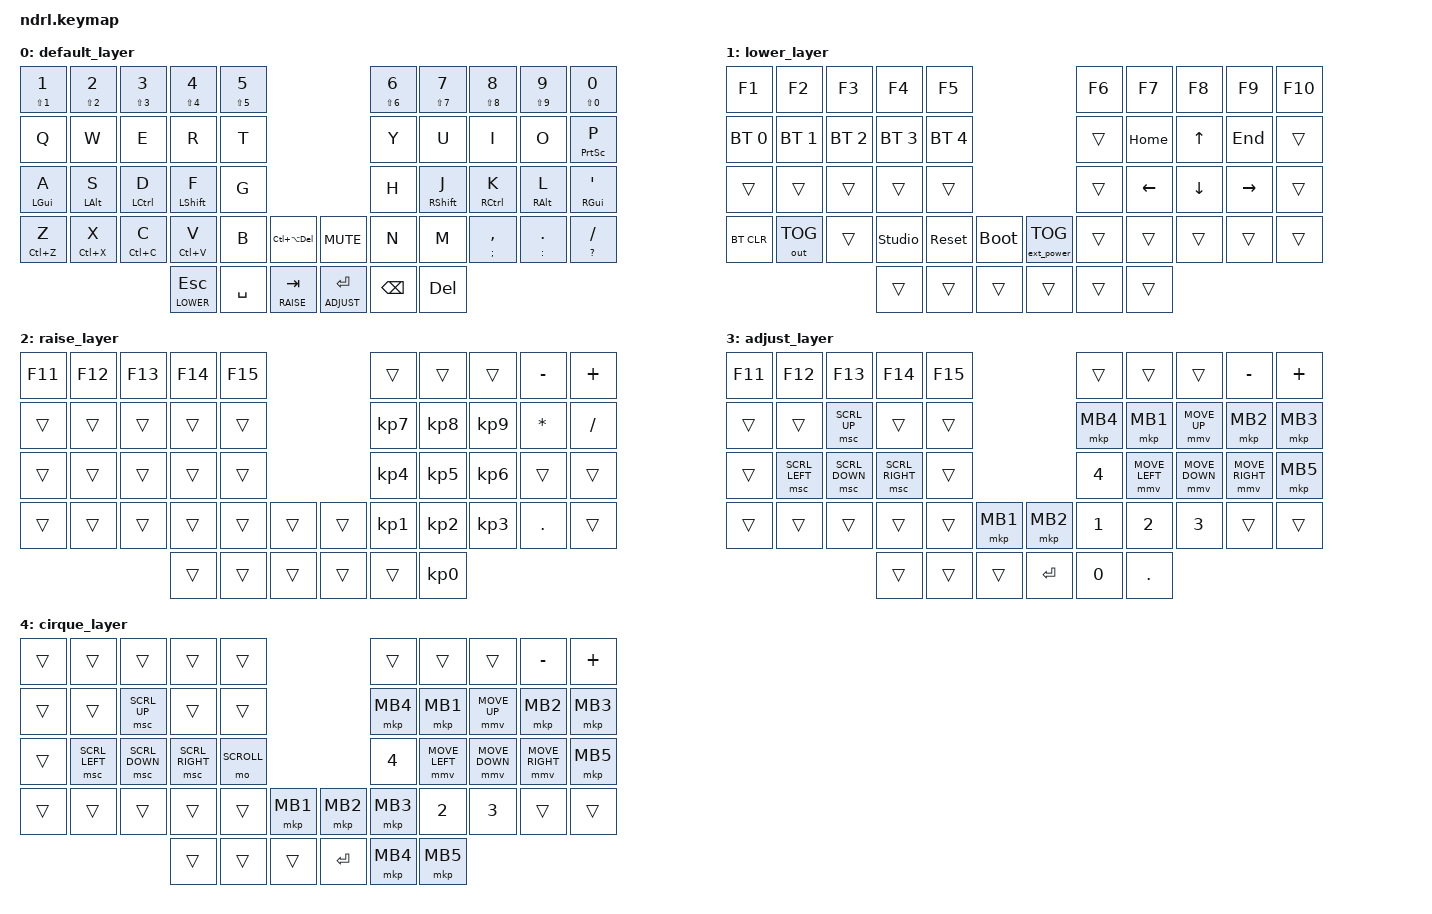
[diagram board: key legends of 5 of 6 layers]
/*
 * Copyright (c) 2024 idesignstuff
 *
 * SPDX-License-Identifier: MIT
 */

#include <behaviors.dtsi>
#include <dt-bindings/zmk/keys.h>
#include <dt-bindings/zmk/bt.h>
#include <dt-bindings/zmk/outputs.h>
#include <zephyr/dt-bindings/input/input-event-codes.h>
#include <input/processors.dtsi>
#include <dt-bindings/zmk/input_transform.h>
#include <dt-bindings/zmk/ext_power.h>
#include <dt-bindings/zmk/pointing.h>

#define DEFAULT 0
#define LOWER   1
#define RAISE   2
#define ADJUST  3
#define CIRQUE  4
#define SCROLL  5
 / {
     glidepoint_listener {
        compatible = "zmk,input-listener";
        device = <&glidepoint>;
        input-processors = 
        <&zip_xy_transform (INPUT_TRANSFORM_XY_SWAP |INPUT_TRANSFORM_X_INVERT | INPUT_TRANSFORM_Y_INVERT)>,
        <&zip_temp_layer 4 1000>;
     };
      scroller {
        layers = <1>;
        input-processors =
            <&zip_xy_to_scroll_mapper>,
            <&zip_scroll_transform (INPUT_TRANSFORM_XY_SWAP | INPUT_TRANSFORM_Y_INVERT)>,
            <&zip_scroll_scaler 1 3>;
    };
   };

/ {
    behaviors {
        // Home row mod tap settings
        hrm: home_row_mods {
            compatible = "zmk,behavior-hold-tap";
            label = "HOME_ROW_MODS";
            #binding-cells = <2>;
            tapping-term-ms = <300>;
            quick-tap-ms = <0>;
            flavor = "tap-preferred";
            bindings = <&kp>, <&kp>;
        }; // end home row mod tap settings

        pht: positional_hold_tap {
            compatible = "zmk,behavior-hold-tap";
            label = "POSITIONAL_HOLD_TAP";
            #binding-cells = <2>;
            flavor = "hold-preferred";
            tapping-term-ms = <400>;
            quick-tap-ms = <200>;
            bindings = <&kp>, <&kp>;
            hold-trigger-key-positions = <1>;    // <---[[the W key]]
            }; //end positional hold tap

       rpi: require_prior_idle {
         compatible = "zmk,behavior-hold-tap";
         #binding-cells = <2>;
         flavor = "tap-preferred";
         tapping-term-ms = <200>;
         quick-tap-ms = <200>;
         require-prior-idle-ms = <80>;
         bindings = <&kp>, <&kp>;
         }; //end require prior idle
    }; // end behaviors
};
/ {
    conditional_layers {
        compatible = "zmk,conditional-layers";
        tri_layer {
            if-layers = <1 2>;
            then-layer = <5>;
        };
    };
};
/ {
    combos {
        compatible = "zmk,combos";

        combo_grave {
            bindings = <&kp GRAVE>;
            key-positions = <0 1>;
            require-prior-idle-ms = <100>;
            layers = <0>;
        };

        combo_capslock {
            bindings = <&caps_word>;
            key-positions = <23 26>;
            require-prior-idle-ms = <100>;
            layers = <0>;
        };

        combo_hyphen {
            bindings = <&kp MINUS>;
            key-positions = <8 9>;
            require-prior-idle-ms = <100>;
            layers = <0>;
        };

        combo_equals {
            bindings = <&kp EQUAL>;
            key-positions = <18 19>;
            require-prior-idle-ms = <100>;
            layers = <0>;
        };

        combo_backslash {
            bindings = <&kp BSLH>;
            key-positions = <38 39>;
            require-prior-idle-ms = <100>;
            layers = <0>;
        };

        combo_rcd {
            bindings = <&rcd_macro>;
            key-positions = <12 13>;
            require-prior-idle-ms = <250>;
        };

        combo_rtc {
            bindings = <&rtc_macro>;
            key-positions = <13 14>;
            require-prior-idle-ms = <250>;
        };

        open_par {
            bindings = <&kp LEFT_PARENTHESIS>;
            key-positions = <43 44>;
            require-prior-idle-ms = <100>;
        };

        close_par {
            bindings = <&kp RIGHT_PARENTHESIS>;
            key-positions = <45 46>;
            require-prior-idle-ms = <100>;
        };

        open_brkt {
            bindings = <&kp LEFT_BRACKET>;
            key-positions = <42 43>;
            require-prior-idle-ms = <100>;
        };

        close_brkt {
            bindings = <&kp RIGHT_BRACKET>;
            key-positions = <46 47>;
            require-prior-idle-ms = <100>;
        };

        wes_combo {
            bindings = <&wes_macro>;
            key-positions = <11 12>;
            require-prior-idle-ms = <250>;
        };
        cdr_combo {
            bindings = <&cdr_macro>;
            key-positions = <32 33>;
            require-prior-idle-ms = <250>;
        };
        ext_combo {
            bindings = <&ext_power EP_TOG>;
            key-positions = <2 9>;
            require-prior-idle-ms = <250>;
        };
        mmb_combo {
            bindings = <&mkp MB3>;
            key-positions = <35 36>;
            require-prior-idle-ms = <250>;
        };
        
    };
};

/ {
    macros {
        rcd_macro: rcd_macro {
            compatible = "zmk,behavior-macro";
            #binding-cells = <0>;
            bindings = <&kp R &kp I &kp T &kp C &kp H &kp I &kp E &kp UNDER &kp C &kp H &kp R &kp I &kp S &kp T &kp I &kp A &kp N &kp UNDER &kp D &kp AT &kp C &kp A &kp T &kp DOT &kp C &kp O &kp M>;
            label = "RCD_MACRO";
            wait-ms = <10>;
            tap-ms = <10>;
        };
        rtc_macro: rtc_macro {
            compatible = "zmk,behavior-macro";
            #binding-cells = <0>;
            bindings = <&kp R &kp I &kp T &kp C &kp H &kp C &kp D>;
            label = "RTC_MACRO";
            wait-ms = <10>;
            tap-ms = <10>;
        };
        wes_macro: wes_macro {
            compatible = "zmk,behavior-macro";
            #binding-cells = <0>;
            bindings = <&kp W &kp E &kp DOT &kp E &kp A &kp T &kp DOT &kp S &kp P &kp A &kp M &kp A &kp L &kp O &kp T &kp AT &kp G &kp M &kp A &kp I &kp L &kp DOT &kp C &kp O &kp M>;
            label = "WES_MACRO";
            wait-ms = <10>;
            tap-ms = <10>;
        };
        cdr_macro: cdr_macro {
            compatible = "zmk,behavior-macro";
            #binding-cells = <0>;
            bindings = <&kp C &kp H &kp R &kp I &kp S &kp T &kp I &kp A &kp N &kp DOT &kp D &kp DOT &kp R &kp I &kp T &kp C &kp H &kp I &kp E &kp AT &kp G &kp M &kp A &kp I &kp L &kp DOT &kp C &kp O &kp M>;
            label = "CDR_MACRO";
            wait-ms = <10>;
            tap-ms = <10>;
        };
    };
    keymap {
        compatible = "zmk,keymap";

        default_layer {
            bindings = <
//╭──────────────┬──────────────┬──────────────┬──────────────┬──────────────╮                                     ╭──────────────┬──────────────┬──────────────┬──────────────┬────────────────╮
   &rpi LS(N1) N1 &rpi LS(N2) N2 &rpi LS(N3) N3 &rpi LS(N4) N4 &rpi LS(N5) N5                                       &rpi LS(N6) N6 &rpi LS(N7) N7 &rpi LS(N8) N8 &rpi LS(N9) N9  &rpi LS(N0) N0
//├──────────────┼──────────────┼──────────────┼──────────────┼──────────────┤                                     ├──────────────┼──────────────┼──────────────┼──────────────┼────────────────┤
        &kp Q          &kp W         &kp E          &kp R           &kp T                                              &kp Y           &kp U            &kp I         &kp O        &rpi PSCRN P
//├──────────────┼──────────────┼──────────────┼──────────────┼──────────────┤                                     ├──────────────┼──────────────┼──────────────┼──────────────┼────────────────┤
     &hrm LGUI A   &hrm LALT S      &hrm LCTL D  &hrm LSHFT F       &kp G                                               &kp H        &hrm RSHFT J    &hrm RCTL K    &hrm RALT L  &hrm RGUI APOS
//├──────────────┼──────────────┼──────────────┼──────────────┼──────────────┼─────────────────╮ ╭─────────────────┼──────────────┼──────────────┼──────────────┼──────────────┼────────────────┤ 
    &rpi LC(Z) Z   &rpi LC(X) X   &rpi LC(C) C   &rpi LC(V) V       &kp B      &kp LC(LA(DEL))        &kp C_MUTE         &kp N           &kp M   &rpi SEMI COMMA &rpi COLON DOT  &rpi QMARK FSLH
//╰──────────────┴──────────────┴──────────────┼──────────────┼──────────────┼─────────────────┤ ├─────────────────┼──────────────┼──────────────┼──────────────┴──────────────┴────────────────╯ 
                                                 &lt LOWER ESC     &kp SPC      &lt RAISE TAB       &lt ADJUST RET      &kp BSPC        &kp DEL
//                                             ╰──────────────┴──────────────┴─────────────────╯ ╰─────────────────┴──────────────┴──────────────╯
            >;
        }; // end default layer
        
        lower_layer {
            bindings = <
//╭──────────────┬──────────────┬──────────────┬──────────────┬──────────────╮                                     ╭──────────────┬──────────────┬──────────────┬──────────────┬─────────────────────╮
        &kp F1        &kp F2         &kp F3         &kp F4         &kp F5                                               &kp F6         &kp F7          &kp F8        &kp F9           &kp F10
//├──────────────┼──────────────┼──────────────┼──────────────┼──────────────┤                                     ├──────────────┼──────────────┼──────────────┼──────────────┼─────────────────────┤
    &bt BT_SEL 0  &bt BT_SEL 1   &bt BT_SEL 2   &bt BT_SEL 3    &bt BT_SEL 4                                            &trans        &kp HOME        &kp UP        &kp END           &trans
//├──────────────┼──────────────┼──────────────┼──────────────┼──────────────┤                                     ├──────────────┼──────────────┼──────────────┼──────────────┼─────────────────────┤ 
       &trans         &trans         &trans         &trans         &trans                                               &trans         &kp LEFT       &kp DOWN       &kp RIGHT        &trans
//├──────────────┼──────────────┼──────────────┼──────────────┼──────────────┼─────────────────╮ ╭─────────────────┼──────────────┼──────────────┼──────────────┼──────────────┼─────────────────────┤ 
    &bt BT_CLR     &out OUT_TOG      &trans     &studio_unlock    &sys_reset    &bootloader       &ext_power EP_TOG     &trans        &trans          &trans         &trans           &trans
//╰──────────────┴──────────────┴──────────────┴──────────────┴──────────────┴─────────────────┤ ├─────────────────┴──────────────┴──────────────┴──────────────┴──────────────┴─────────────────────╯ 
                                                    &trans         &trans         &trans            &trans           &trans          &trans
//                                             ╰──────────────┴──────────────┴─────────────────╯ ╰─────────────────┴──────────────┴──────────────╯
            >;
        }; // end lower layer

        raise_layer {
            bindings = <
//╭──────────────┬──────────────┬──────────────┬──────────────┬──────────────╮                                     ╭──────────────┬──────────────┬──────────────┬──────────────┬─────────────────────╮
        &kp F11       &kp F12        &kp F13        &kp F14        &kp F15                                              &trans         &trans          &trans       &kp MINUS      &kp PLUS
//├──────────────┼──────────────┼──────────────┼──────────────┼──────────────┤                                     ├──────────────┼──────────────┼──────────────┼──────────────┼─────────────────────┤
        &trans        &trans         &trans         &trans         &trans                                               &kp KP_N7    &kp KP_N8       &kp KP_N9    &kp ASTERISK     &kp SLASH
//├──────────────┼──────────────┼──────────────┼──────────────┼──────────────┤                                     ├──────────────┼──────────────┼──────────────┼──────────────┼─────────────────────┤ 
        &trans        &trans         &trans         &trans         &trans                                               &kp KP_N4     &kp KP_N5      &kp KP_N6        &trans         &trans
//├──────────────┼──────────────┼──────────────┼──────────────┼──────────────┼─────────────────╮ ╭─────────────────┼──────────────┼──────────────┼──────────────┼──────────────┼─────────────────────┤ 
        &trans        &trans         &trans         &trans         &trans          &trans                &trans         &kp KP_N1     &kp KP_N2      &kp KP_N3       &kp DOT         &trans
//╰──────────────┴──────────────┴──────────────┴──────────────┴──────────────┴─────────────────┤ ├─────────────────┴──────────────┴──────────────┴──────────────┴──────────────┴─────────────────────╯ 
                                                     &trans           &trans       &trans               &trans          &trans        &kp KP_N0 
//                                             ╰──────────────┴──────────────┴─────────────────╯ ╰─────────────────┴──────────────┴──────────────╯
            >;

        }; // end raise layer

        adjust_layer {
            bindings = <
//╭──────────────┬──────────────┬──────────────┬──────────────┬──────────────╮               ─────                 ╭──────────────┬──────────────┬──────────────┬──────────────┬─────────────────────╮
        &kp F11       &kp F12        &kp F13        &kp F14        &kp F15                                              &trans         &trans          &trans       &kp MINUS      &kp PLUS
//├──────────────┼──────────────┼──────────────┼──────────────┼──────────────┤         |     Cirque     |          ├──────────────┼──────────────┼──────────────┼──────────────┼─────────────────────┤
        &trans        &trans      &msc SCRL_UP      &trans         &trans                                               &mkp MB4        &mkp MB1   &mmv MOVE_UP      &mkp MB2       &mkp MB3
//├──────────────┼──────────────┼──────────────┼──────────────┼──────────────┤               ─────                 ├──────────────┼──────────────┼──────────────┼──────────────┼─────────────────────┤ 
        &trans    &msc SCRL_LEFT &msc SCRL_DOWN &msc SCRL_RIGHT     &trans                                               &kp N4     &mmv MOVE_LEFT &mmv MOVE_DOWN &mmv MOVE_RIGHT    &mkp MB5
//├──────────────┼──────────────┼──────────────┼──────────────┼──────────────┼─────────────────╮ ╭─────────────────┼──────────────┼──────────────┼──────────────┼──────────────┼─────────────────────┤ 
        &trans        &trans         &trans         &trans         &trans          &mkp MB1            &mkp MB2         &kp N1         &kp N2          &kp N3        &trans         &trans
//╰──────────────┴──────────────┴──────────────┴──────────────┴──────────────┴─────────────────┤ ├─────────────────┴──────────────┴──────────────┴──────────────┴──────────────┴─────────────────────╯ 
                                                     &trans           &trans       &trans               &kp ENTER       &kp N0         &kp DOT       
//                                             ╰──────────────┴──────────────┴─────────────────╯ ╰─────────────────┴──────────────┴──────────────╯
            >;

        }; // end adjust layer

        cirque_layer {
            bindings = <
//╭──────────────┬──────────────┬──────────────┬──────────────┬──────────────╮               ─────                 ╭──────────────┬──────────────┬──────────────┬──────────────┬─────────────────────╮
        &trans        &trans         &trans         &trans         &trans                                               &trans         &trans          &trans       &kp MINUS      &kp PLUS
//├──────────────┼──────────────┼──────────────┼──────────────┼──────────────┤         |     Cirque     |          ├──────────────┼──────────────┼──────────────┼──────────────┼─────────────────────┤
        &trans        &trans      &msc SCRL_UP      &trans         &trans                                               &mkp MB4        &mkp MB1   &mmv MOVE_UP      &mkp MB2       &mkp MB3
//├──────────────┼──────────────┼──────────────┼──────────────┼──────────────┤               ─────                 ├──────────────┼──────────────┼──────────────┼──────────────┼─────────────────────┤ 
        &trans    &msc SCRL_LEFT &msc SCRL_DOWN &msc SCRL_RIGHT   &mo SCROLL                                            &kp N4     &mmv MOVE_LEFT &mmv MOVE_DOWN &mmv MOVE_RIGHT    &mkp MB5
//├──────────────┼──────────────┼──────────────┼──────────────┼──────────────┼─────────────────╮ ╭─────────────────┼──────────────┼──────────────┼──────────────┼──────────────┼─────────────────────┤ 
        &trans        &trans         &trans         &trans         &trans          &mkp MB1            &mkp MB2         &mkp MB3        &kp N2          &kp N3        &trans         &trans
//╰──────────────┴──────────────┴──────────────┴──────────────┴──────────────┴─────────────────┤ ├─────────────────┴──────────────┴──────────────┴──────────────┴──────────────┴─────────────────────╯ 
                                                     &trans         &trans          &trans             &kp ENTER       &mkp MB4       &mkp MB5       
//                                             ╰──────────────┴──────────────┴─────────────────╯ ╰─────────────────┴──────────────┴──────────────╯
            >;

        }; // end cirque layer

        scroll_layer {
            bindings = <
//╭──────────────┬──────────────┬──────────────┬──────────────┬──────────────╮               ─────                 ╭──────────────┬──────────────┬──────────────┬───────────────┬─────────────────────╮
        &trans        &trans         &trans         &trans         &trans                                               &trans         &trans          &trans       &kp MINUS      &kp PLUS
//├──────────────┼──────────────┼──────────────┼──────────────┼──────────────┤         |     Cirque     |          ├──────────────┼──────────────┼──────────────┼───────────────┼─────────────────────┤
        &trans        &trans      &msc SCRL_UP      &trans         &trans                                               &mkp MB4        &mkp MB1   &mmv MOVE_UP      &mkp MB2       &mkp MB3
//├──────────────┼──────────────┼──────────────┼──────────────┼──────────────┤               ─────                 ├──────────────┼──────────────┼──────────────┼───────────────┼─────────────────────┤ 
        &trans    &msc SCRL_LEFT &msc SCRL_DOWN &msc SCRL_RIGHT   &mkp MB1                                              &kp N4     &mmv MOVE_LEFT &mmv MOVE_DOWN &mmv MOVE_RIGHT    &mkp MB5
//├──────────────┼──────────────┼──────────────┼──────────────┼──────────────┼─────────────────╮ ╭─────────────────┼──────────────┼──────────────┼──────────────┼───────────────┼─────────────────────┤ 
        &trans        &trans         &trans         &trans         &trans          &mkp MB3            &mkp MB2         &kp N1         &kp N2          &kp N3        &trans         &trans
//╰──────────────┴──────────────┴──────────────┴──────────────┴──────────────┴─────────────────┤ ├─────────────────┴──────────────┴──────────────┴──────────────┴───────────────┴─────────────────────╯ 
                                                     &trans           &trans       &trans               &kp ENTER       &kp N0                
//                                             ╰──────────────┴──────────────┴─────────────────╯ ╰─────────────────┴──────────────┴──────────────╯
            >;

        }; // end scroll layer


        extra1 {
            status = "reserved";
        };

        extra2 {
            status = "reserved";
        };

    }; // end keymap

 }; // top node end
